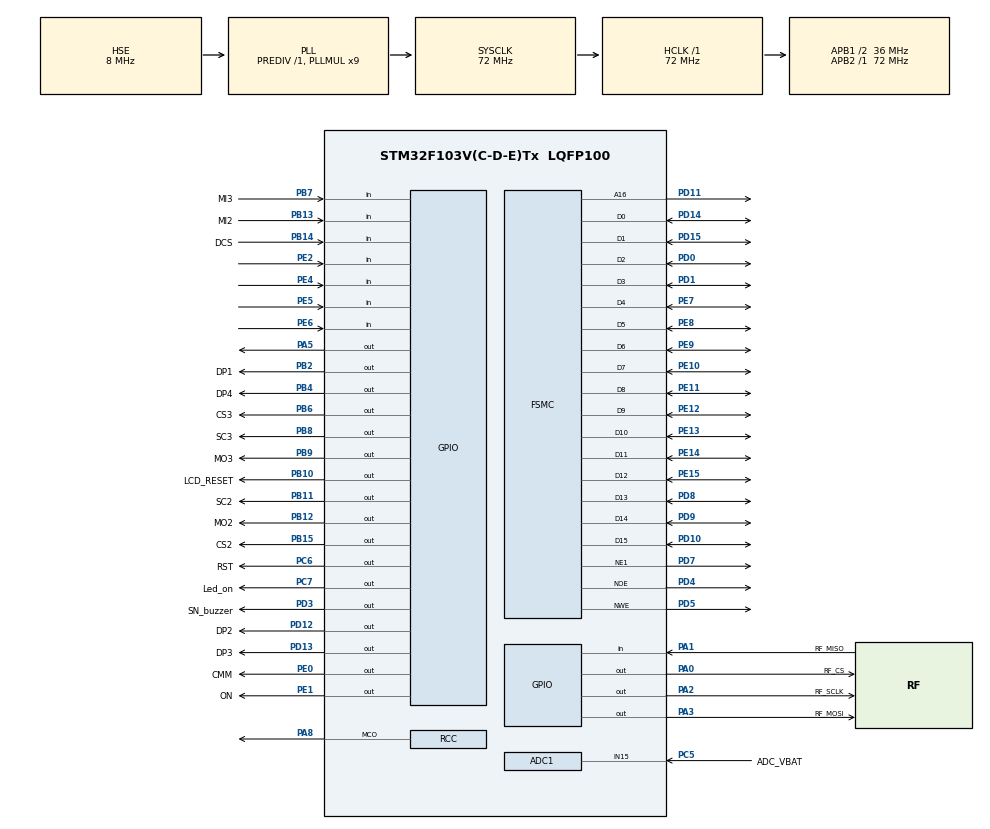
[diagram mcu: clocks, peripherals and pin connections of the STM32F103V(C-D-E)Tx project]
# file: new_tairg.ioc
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ADC1.Channel-1\#ChannelRegularConversion=ADC_CHANNEL_15
ADC1.ExternalTrigConv=ADC_EXTERNALTRIGCONV_T8_TRGO
ADC1.NbrOfConversion=1
ADC1.NbrOfConversionFlag=1
ADC1.Rank-1\#ChannelRegularConversion=1
ADC1.SamplingTime-1\#ChannelRegularConversion=ADC_SAMPLETIME_239CYCLES_5
ADC1.master=1
Dma.ADC1.0.Direction=DMA_PERIPH_TO_MEMORY
Dma.ADC1.0.Instance=DMA1_Channel1
Dma.ADC1.0.MemDataAlignment=DMA_MDATAALIGN_HALFWORD
Dma.ADC1.0.MemInc=DMA_MINC_ENABLE
Dma.ADC1.0.Mode=DMA_CIRCULAR
Dma.ADC1.0.PeriphDataAlignment=DMA_PDATAALIGN_HALFWORD
Dma.ADC1.0.PeriphInc=DMA_PINC_DISABLE
Dma.ADC1.0.Priority=DMA_PRIORITY_LOW
Dma.Request0=ADC1
FREERTOS.Tasks01=defaultTask,0,1024,StartDefaultTask,Default,NULL,Dynamic,NULL,NULL;kbTask,0,1024,kbTaskProc,Default,NULL,Dynamic,NULL,NULL;MeasureTask,0,512,MeasureTaskProc,Default,NULL,Dynamic,NULL,NULL;rfTask,0,256,RfTaskStart,Default,NULL,Dynamic,NULL,NULL
FREERTOS.configCHECK_FOR_STACK_OVERFLOW=2
FREERTOS.configRECORD_STACK_HIGH_ADDRESS=1
FREERTOS.configTOTAL_HEAP_SIZE=49000
FSMC.AddressSetupTime1=1
FSMC.BusTurnAroundDuration1=1
FSMC.DataSetupTime1=1
IWDG.Prescaler=IWDG_PRESCALER_256
IWDG.Reload=480
Mcu.Family=STM32F1
Mcu.Name=STM32F103V(C-D-E)Tx
Mcu.Package=LQFP100
NVIC.DMA1_Channel1_IRQn=true\:5\:0\:false\:false\:true\:true\:false\:true\:true
NVIC.PriorityGroup=NVIC_PRIORITYGROUP_4
NVIC.TIM7_IRQn=true\:0\:0\:false\:false\:true\:false\:false\:true\:true
NVIC.TimeBase=TIM7_IRQn
NVIC.TimeBaseIP=TIM7
OSC_IN.Mode=HSE-External-Oscillator
OSC_IN.Signal=RCC_OSC_IN
OSC_OUT.Mode=HSE-External-Oscillator
OSC_OUT.Signal=RCC_OSC_OUT
PA0-WKUP.GPIO_Label=RF_CS
PA0-WKUP.GPIO_Speed=GPIO_SPEED_FREQ_HIGH
PA0-WKUP.Signal=GPIO_Output
PA1.GPIO_Label=RF_MISO
PA1.Signal=GPIO_Input
PA13.Mode=JTAG_4_pins
PA13.Signal=SYS_JTMS-SWDIO
PA14.Mode=JTAG_4_pins
PA14.Signal=SYS_JTCK-SWCLK
PA15.Mode=JTAG_4_pins
PA15.Signal=SYS_JTDI
PA2.GPIO_Label=RF_SCLK
PA2.GPIO_Speed=GPIO_SPEED_FREQ_HIGH
PA2.Signal=GPIO_Output
PA3.GPIO_Label=RF_MOSI
PA3.GPIO_Speed=GPIO_SPEED_FREQ_HIGH
PA3.Signal=GPIO_Output
PA5.Signal=GPIO_Output
PA8.Mode=Clock-out
PA8.Signal=RCC_MCO
PB10.GPIO_Label=LCD_RESET
PB10.Signal=GPIO_Output
PB11.GPIO_Label=SC2
PB11.Signal=GPIO_Output
PB12.GPIO_Label=MO2
PB12.Signal=GPIO_Output
PB13.GPIO_Label=MI2
PB13.Signal=GPIO_Input
PB14.GPIO_Label=DCS
PB14.Signal=GPIO_Input
PB15.GPIO_Label=CS2
PB15.Signal=GPIO_Output
PB2.GPIO_Label=DP1
PB2.Signal=GPIO_Output
PB3.Mode=JTAG_4_pins
PB3.Signal=SYS_JTDO-TRACESWO
PB4.GPIO_Label=DP4
PB4.Signal=GPIO_Output
PB6.GPIO_Label=CS3
PB6.GPIO_Speed=GPIO_SPEED_FREQ_HIGH
PB6.PinState=GPIO_PIN_SET
PB6.Signal=GPIO_Output
PB7.GPIO_Label=MI3
PB7.Signal=GPIO_Input
PB8.GPIO_Label=SC3
PB8.GPIO_Speed=GPIO_SPEED_FREQ_HIGH
PB8.Signal=GPIO_Output
PB9.GPIO_Label=MO3
PB9.Signal=GPIO_Output
PC14-OSC32_IN.Mode=LSE-External-Oscillator
PC14-OSC32_IN.Signal=RCC_OSC32_IN
PC15-OSC32_OUT.Mode=LSE-External-Oscillator
PC15-OSC32_OUT.Signal=RCC_OSC32_OUT
PC5.GPIO_Label=ADC_VBAT
PC5.Signal=ADCx_IN15
PC6.GPIO_Label=RST
PC6.Signal=GPIO_Output
PC7.GPIO_Label=Led_on
PC7.PinState=GPIO_PIN_RESET
PC7.Signal=GPIO_Output
PD0.Mode=16b-d1
PD0.Signal=FSMC_D2
PD1.Mode=16b-d1
PD1.Signal=FSMC_D3
PD10.Mode=16b-d1
PD10.Signal=FSMC_D15
PD11.Mode=A16_1
PD11.Signal=FSMC_A16
PD12.GPIO_Label=DP2
PD12.Signal=GPIO_Output
PD13.GPIO_Label=DP3
PD13.Signal=GPIO_Output
PD14.Mode=16b-d1
PD14.Signal=FSMC_D0
PD15.Mode=16b-d1
PD15.Signal=FSMC_D1
PD3.GPIO_Label=SN_buzzer
PD3.Signal=GPIO_Output
PD4.Mode=Lcd1
PD4.Signal=FSMC_NOE
PD5.Mode=Lcd1
PD5.Signal=FSMC_NWE
PD7.Mode=NorPsramChipSelect1_1
PD7.Signal=FSMC_NE1
PD8.Mode=16b-d1
PD8.Signal=FSMC_D13
PD9.Mode=16b-d1
PD9.Signal=FSMC_D14
PE0.GPIO_Label=CMM
PE0.Signal=GPIO_Output
PE1.GPIO_Label=ON
PE1.PinState=GPIO_PIN_SET
PE1.Signal=GPIO_Output
PE10.Mode=16b-d1
PE10.Signal=FSMC_D7
PE11.Mode=16b-d1
PE11.Signal=FSMC_D8
PE12.Mode=16b-d1
PE12.Signal=FSMC_D9
PE13.Mode=16b-d1
PE13.Signal=FSMC_D10
PE14.Mode=16b-d1
PE14.Signal=FSMC_D11
PE15.Mode=16b-d1
PE15.Signal=FSMC_D12
PE2.Signal=GPIO_Input
PE4.GPIO_PuPd=GPIO_PULLUP
PE4.Signal=GPIO_Input
PE5.GPIO_PuPd=GPIO_PULLUP
PE5.Signal=GPIO_Input
PE6.GPIO_PuPd=GPIO_PULLUP
PE6.Signal=GPIO_Input
PE7.Mode=16b-d1
PE7.Signal=FSMC_D4
PE8.Mode=16b-d1
PE8.Signal=FSMC_D5
PE9.Mode=16b-d1
PE9.Signal=FSMC_D6
ProjectManager.HeapSize=0x0
ProjectManager.StackSize=0x400
ProjectManager.TargetToolchain=STM32CubeIDE
RCC.ADCPresc=RCC_ADCPCLK2_DIV6
RCC.AHBFreq_Value=72000000
RCC.APB1CLKDivider=RCC_HCLK_DIV2
RCC.APB1Freq_Value=36000000
RCC.APB1TimFreq_Value=72000000
RCC.APB2Freq_Value=72000000
RCC.APB2TimFreq_Value=72000000
RCC.HCLKFreq_Value=72000000
RCC.PLLMUL=RCC_PLL_MUL9
RCC.PLLSourceVirtual=RCC_PLLSOURCE_HSE
RCC.RCC_MCOSource=RCC_MCO1SOURCE_HSE
RCC.RTCClockSelection=RCC_RTCCLKSOURCE_LSE
RCC.SYSCLKFreq_VALUE=72000000
RCC.SYSCLKSource=RCC_SYSCLKSOURCE_PLLCLK
RCC.USBFreq_Value=48000000
RCC.USBPrescaler=RCC_USBCLKSOURCE_PLL_DIV1_5
SH.ADCx_IN15.0=ADC1_IN15,IN15
TIM8.Period=1000
TIM8.Prescaler=71
TIM8.TIM_MasterOutputTrigger=TIM_TRGO_UPDATE
TIM8.TIM_MasterSlaveMode=TIM_MASTERSLAVEMODE_ENABLE
VP_FREERTOS_VS_CMSIS_V1.Mode=CMSIS_V1
VP_IWDG_VS_IWDG.Mode=IWDG_Activate
VP_RTC_VS_RTC_Activate.Mode=RTC_Enabled
VP_SYS_VS_tim7.Mode=TIM7
VP_TIM8_VS_ClockSourceINT.Mode=Internal
board=custom

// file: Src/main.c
/* USER CODE BEGIN Header */
/**
  ******************************************************************************
  * @file           : main.c
  * @brief          : Main program body
  ******************************************************************************
  * This notice applies to any and all portions of this file
  * that are not between comment pairs USER CODE BEGIN and
  * USER CODE END. Other portions of this file, whether
  * inserted by the user or by software development tools
  * are owned by their respective copyright owners.
  *
  * Copyright (c) 2019 STMicroelectronics International N.V.
  * All rights reserved.
  *
  * Redistribution and use in source and binary forms, with or without
  * modification, are permitted, provided that the following conditions are met:
  *
  * 1. Redistribution of source code must retain the above copyright notice,
  *    this list of conditions and the following disclaimer.
  * 2. Redistributions in binary form must reproduce the above copyright notice,
  *    this list of conditions and the following disclaimer in the documentation
  *    and/or other materials provided with the distribution.
  * 3. Neither the name of STMicroelectronics nor the names of other
  *    contributors to this software may be used to endorse or promote products
  *    derived from this software without specific written permission.
  * 4. This software, including modifications and/or derivative works of this
  *    software, must execute solely and exclusively on microcontroller or
  *    microprocessor devices manufactured by or for STMicroelectronics.
  * 5. Redistribution and use of this software other than as permitted under
  *    this license is void and will automatically terminate your rights under
  *    this license.
  *
  * THIS SOFTWARE IS PROVIDED BY STMICROELECTRONICS AND CONTRIBUTORS "AS IS"
  * AND ANY EXPRESS, IMPLIED OR STATUTORY WARRANTIES, INCLUDING, BUT NOT
  * LIMITED TO, THE IMPLIED WARRANTIES OF MERCHANTABILITY, FITNESS FOR A
  * PARTICULAR PURPOSE AND NON-INFRINGEMENT OF THIRD PARTY INTELLECTUAL PROPERTY
  * RIGHTS ARE DISCLAIMED TO THE FULLEST EXTENT PERMITTED BY LAW. IN NO EVENT
  * SHALL STMICROELECTRONICS OR CONTRIBUTORS BE LIABLE FOR ANY DIRECT, INDIRECT,
  * INCIDENTAL, SPECIAL, EXEMPLARY, OR CONSEQUENTIAL DAMAGES (INCLUDING, BUT NOT
  * LIMITED TO, PROCUREMENT OF SUBSTITUTE GOODS OR SERVICES; LOSS OF USE, DATA,
  * OR PROFITS; OR BUSINESS INTERRUPTION) HOWEVER CAUSED AND ON ANY THEORY OF
  * LIABILITY, WHETHER IN CONTRACT, STRICT LIABILITY, OR TORT (INCLUDING
  * NEGLIGENCE OR OTHERWISE) ARISING IN ANY WAY OUT OF THE USE OF THIS SOFTWARE,
  * EVEN IF ADVISED OF THE POSSIBILITY OF SUCH DAMAGE.
  *
  ******************************************************************************
  */
/* USER CODE END Header */
#include "main.h"
#include "cmsis_os.h"

 ADC_HandleTypeDef hadc1;
DMA_HandleTypeDef hdma_adc1;

IWDG_HandleTypeDef hiwdg;

RTC_HandleTypeDef hrtc;

TIM_HandleTypeDef htim8;

SRAM_HandleTypeDef hsram1;

osThreadId defaultTaskHandle;
osThreadId kbTaskHandle;
osThreadId MeasureTaskHandle;
osThreadId rfTaskHandle;
/* USER CODE BEGIN PV */
/* Private variables ---------------------------------------------------------*/

/* USER CODE END PV */

void SystemClock_Config(void);
static void MX_GPIO_Init(void);
static void MX_DMA_Init(void);
static void MX_FSMC_Init(void);
static void MX_ADC1_Init(void);
static void MX_RTC_Init(void);
static void MX_TIM8_Init(void);
static void MX_IWDG_Init(void);
void StartDefaultTask(void const * argument);
void kbTaskProc(void const * argument);
void MeasureTaskProc(void const * argument);
void RfTaskStart(void const * argument);

/* USER CODE BEGIN PFP */
/* Private function prototypes -----------------------------------------------*/

/* USER CODE END PFP */

int main(void)
{

  /* MCU Configuration--------------------------------------------------------*/

  /* Reset of all peripherals, Initializes the Flash interface and the Systick. */
  HAL_Init();

  /* Configure the system clock */
  SystemClock_Config();

  /* Initialize all configured peripherals */
  MX_GPIO_Init();
  MX_DMA_Init();
  MX_FSMC_Init();
  MX_ADC1_Init();
  MX_RTC_Init();
  MX_TIM8_Init();
  MX_IWDG_Init();
  /* USER CODE BEGIN 2 */
  init();
  /* USER CODE END 2 */

  /* Create the thread(s) */
  /* definition and creation of defaultTask */
  osThreadDef(defaultTask, StartDefaultTask, osPriorityNormal, 0, 1024);
  defaultTaskHandle = osThreadCreate(osThread(defaultTask), NULL);

  /* definition and creation of kbTask */
  osThreadDef(kbTask, kbTaskProc, osPriorityNormal, 0, 1024);
  kbTaskHandle = osThreadCreate(osThread(kbTask), NULL);

  /* definition and creation of MeasureTask */
  osThreadDef(MeasureTask, MeasureTaskProc, osPriorityNormal, 0, 512);
  MeasureTaskHandle = osThreadCreate(osThread(MeasureTask), NULL);

  /* definition and creation of rfTask */
  osThreadDef(rfTask, RfTaskStart, osPriorityNormal, 0, 256);
  rfTaskHandle = osThreadCreate(osThread(rfTask), NULL);

  /* Start scheduler */
  osKernelStart();

  /* We should never get here as control is now taken by the scheduler */
  /* Infinite loop */
  while (1)
  {

  }
}

void SystemClock_Config(void)
{
  RCC_OscInitTypeDef RCC_OscInitStruct = {0};
  RCC_ClkInitTypeDef RCC_ClkInitStruct = {0};
  RCC_PeriphCLKInitTypeDef PeriphClkInit = {0};

  /** Initializes the RCC Oscillators according to the specified parameters
  * in the RCC_OscInitTypeDef structure.
  */
  RCC_OscInitStruct.OscillatorType = RCC_OSCILLATORTYPE_LSI|RCC_OSCILLATORTYPE_HSE
                              |RCC_OSCILLATORTYPE_LSE;
  RCC_OscInitStruct.HSEState = RCC_HSE_ON;
  RCC_OscInitStruct.HSEPredivValue = RCC_HSE_PREDIV_DIV1;
  RCC_OscInitStruct.LSEState = RCC_LSE_ON;
  RCC_OscInitStruct.HSIState = RCC_HSI_ON;
  RCC_OscInitStruct.LSIState = RCC_LSI_ON;
  RCC_OscInitStruct.PLL.PLLState = RCC_PLL_ON;
  RCC_OscInitStruct.PLL.PLLSource = RCC_PLLSOURCE_HSE;
  RCC_OscInitStruct.PLL.PLLMUL = RCC_PLL_MUL9;
  if (HAL_RCC_OscConfig(&RCC_OscInitStruct) != HAL_OK)
  {
    Error_Handler();
  }

  /** Initializes the CPU, AHB and APB buses clocks
  */
  RCC_ClkInitStruct.ClockType = RCC_CLOCKTYPE_HCLK|RCC_CLOCKTYPE_SYSCLK
                              |RCC_CLOCKTYPE_PCLK1|RCC_CLOCKTYPE_PCLK2;
  RCC_ClkInitStruct.SYSCLKSource = RCC_SYSCLKSOURCE_PLLCLK;
  RCC_ClkInitStruct.AHBCLKDivider = RCC_SYSCLK_DIV1;
  RCC_ClkInitStruct.APB1CLKDivider = RCC_HCLK_DIV2;
  RCC_ClkInitStruct.APB2CLKDivider = RCC_HCLK_DIV1;

  if (HAL_RCC_ClockConfig(&RCC_ClkInitStruct, FLASH_LATENCY_2) != HAL_OK)
  {
    Error_Handler();
  }
  PeriphClkInit.PeriphClockSelection = RCC_PERIPHCLK_RTC|RCC_PERIPHCLK_ADC;
  PeriphClkInit.RTCClockSelection = RCC_RTCCLKSOURCE_LSE;
  PeriphClkInit.AdcClockSelection = RCC_ADCPCLK2_DIV6;
  if (HAL_RCCEx_PeriphCLKConfig(&PeriphClkInit) != HAL_OK)
  {
    Error_Handler();
  }
  HAL_RCC_MCOConfig(RCC_MCO, RCC_MCO1SOURCE_HSE, RCC_MCODIV_1);
}

static void MX_ADC1_Init(void)
{

  ADC_ChannelConfTypeDef sConfig = {0};

  /** Common config
  */
  hadc1.Instance = ADC1;
  hadc1.Init.ScanConvMode = ADC_SCAN_DISABLE;
  hadc1.Init.ContinuousConvMode = DISABLE;
  hadc1.Init.DiscontinuousConvMode = DISABLE;
  hadc1.Init.ExternalTrigConv = ADC_EXTERNALTRIGCONV_T8_TRGO;
  hadc1.Init.DataAlign = ADC_DATAALIGN_RIGHT;
  hadc1.Init.NbrOfConversion = 1;
  if (HAL_ADC_Init(&hadc1) != HAL_OK)
  {
    Error_Handler();
  }

  /** Enable or disable the remapping of ADC1_ETRGREG:
  * ADC1 External Event regular conversion is connected to TIM8 TRG0
  */
  __HAL_AFIO_REMAP_ADC1_ETRGREG_ENABLE();

  /** Configure Regular Channel
  */
  sConfig.Channel = ADC_CHANNEL_15;
  sConfig.Rank = ADC_REGULAR_RANK_1;
  sConfig.SamplingTime = ADC_SAMPLETIME_239CYCLES_5;
  if (HAL_ADC_ConfigChannel(&hadc1, &sConfig) != HAL_OK)
  {
    Error_Handler();
  }

}

static void MX_IWDG_Init(void)
{

  hiwdg.Instance = IWDG;
  hiwdg.Init.Prescaler = IWDG_PRESCALER_256;
  hiwdg.Init.Reload = 480;
  if (HAL_IWDG_Init(&hiwdg) != HAL_OK)
  {
    Error_Handler();
  }

}

static void MX_RTC_Init(void)
{

  /** Initialize RTC Only
  */
  hrtc.Instance = RTC;
  hrtc.Init.AsynchPrediv = RTC_AUTO_1_SECOND;
  hrtc.Init.OutPut = RTC_OUTPUTSOURCE_ALARM;
  if (HAL_RTC_Init(&hrtc) != HAL_OK)
  {
    Error_Handler();
  }

}

static void MX_TIM8_Init(void)
{

  TIM_ClockConfigTypeDef sClockSourceConfig = {0};
  TIM_MasterConfigTypeDef sMasterConfig = {0};

  htim8.Instance = TIM8;
  htim8.Init.Prescaler = 71;
  htim8.Init.CounterMode = TIM_COUNTERMODE_UP;
  htim8.Init.Period = 1000;
  htim8.Init.ClockDivision = TIM_CLOCKDIVISION_DIV1;
  htim8.Init.RepetitionCounter = 0;
  htim8.Init.AutoReloadPreload = TIM_AUTORELOAD_PRELOAD_DISABLE;
  if (HAL_TIM_Base_Init(&htim8) != HAL_OK)
  {
    Error_Handler();
  }
  sClockSourceConfig.ClockSource = TIM_CLOCKSOURCE_INTERNAL;
  if (HAL_TIM_ConfigClockSource(&htim8, &sClockSourceConfig) != HAL_OK)
  {
    Error_Handler();
  }
  sMasterConfig.MasterOutputTrigger = TIM_TRGO_UPDATE;
  sMasterConfig.MasterSlaveMode = TIM_MASTERSLAVEMODE_ENABLE;
  if (HAL_TIMEx_MasterConfigSynchronization(&htim8, &sMasterConfig) != HAL_OK)
  {
    Error_Handler();
  }

}

static void MX_DMA_Init(void)
{

  /* DMA controller clock enable */
  __HAL_RCC_DMA1_CLK_ENABLE();

  /* DMA interrupt init */
  /* DMA1_Channel1_IRQn interrupt configuration */
  HAL_NVIC_SetPriority(DMA1_Channel1_IRQn, 5, 0);
  HAL_NVIC_EnableIRQ(DMA1_Channel1_IRQn);

}

static void MX_GPIO_Init(void)
{
  GPIO_InitTypeDef GPIO_InitStruct = {0};

  /* GPIO Ports Clock Enable */
  __HAL_RCC_GPIOE_CLK_ENABLE();
  __HAL_RCC_GPIOC_CLK_ENABLE();
  __HAL_RCC_GPIOA_CLK_ENABLE();
  __HAL_RCC_GPIOB_CLK_ENABLE();
  __HAL_RCC_GPIOD_CLK_ENABLE();

  /*Configure GPIO pin Output Level */
  HAL_GPIO_WritePin(GPIOA, RF_CS_Pin|RF_SCLK_Pin|RF_MOSI_Pin|GPIO_PIN_5, GPIO_PIN_RESET);

  /*Configure GPIO pin Output Level */
  HAL_GPIO_WritePin(GPIOB, DP1_Pin|LCD_RESET_Pin|SC2_Pin|MO2_Pin
                          |CS2_Pin|DP4_Pin|SC3_Pin|MO3_Pin, GPIO_PIN_RESET);

  /*Configure GPIO pin Output Level */
  HAL_GPIO_WritePin(GPIOD, DP2_Pin|DP3_Pin|SN_buzzer_Pin, GPIO_PIN_RESET);

  /*Configure GPIO pin Output Level */
  HAL_GPIO_WritePin(GPIOC, RST_Pin|Led_on_Pin, GPIO_PIN_RESET);

  /*Configure GPIO pin Output Level */
  HAL_GPIO_WritePin(CS3_GPIO_Port, CS3_Pin, GPIO_PIN_SET);

  /*Configure GPIO pin Output Level */
  HAL_GPIO_WritePin(CMM_GPIO_Port, CMM_Pin, GPIO_PIN_RESET);

  /*Configure GPIO pin Output Level */
  HAL_GPIO_WritePin(ON_GPIO_Port, ON_Pin, GPIO_PIN_SET);

  /*Configure GPIO pin : PE2 */
  GPIO_InitStruct.Pin = GPIO_PIN_2;
  GPIO_InitStruct.Mode = GPIO_MODE_INPUT;
  GPIO_InitStruct.Pull = GPIO_NOPULL;
  HAL_GPIO_Init(GPIOE, &GPIO_InitStruct);

  /*Configure GPIO pin : PE3 */
  GPIO_InitStruct.Pin = GPIO_PIN_3;
  GPIO_InitStruct.Mode = GPIO_MODE_ANALOG;
  HAL_GPIO_Init(GPIOE, &GPIO_InitStruct);

  /*Configure GPIO pins : PE4 PE5 PE6 */
  GPIO_InitStruct.Pin = GPIO_PIN_4|GPIO_PIN_5|GPIO_PIN_6;
  GPIO_InitStruct.Mode = GPIO_MODE_INPUT;
  GPIO_InitStruct.Pull = GPIO_PULLUP;
  HAL_GPIO_Init(GPIOE, &GPIO_InitStruct);

  /*Configure GPIO pins : PC13 PC0 PC1 PC2
                           PC3 PC4 PC8 PC9
                           PC10 PC11 PC12 */
  GPIO_InitStruct.Pin = GPIO_PIN_13|GPIO_PIN_0|GPIO_PIN_1|GPIO_PIN_2
                          |GPIO_PIN_3|GPIO_PIN_4|GPIO_PIN_8|GPIO_PIN_9
                          |GPIO_PIN_10|GPIO_PIN_11|GPIO_PIN_12;
  GPIO_InitStruct.Mode = GPIO_MODE_ANALOG;
  HAL_GPIO_Init(GPIOC, &GPIO_InitStruct);

  /*Configure GPIO pins : RF_CS_Pin RF_SCLK_Pin RF_MOSI_Pin */
  GPIO_InitStruct.Pin = RF_CS_Pin|RF_SCLK_Pin|RF_MOSI_Pin;
  GPIO_InitStruct.Mode = GPIO_MODE_OUTPUT_PP;
  GPIO_InitStruct.Pull = GPIO_NOPULL;
  GPIO_InitStruct.Speed = GPIO_SPEED_FREQ_HIGH;
  HAL_GPIO_Init(GPIOA, &GPIO_InitStruct);

  /*Configure GPIO pin : RF_MISO_Pin */
  GPIO_InitStruct.Pin = RF_MISO_Pin;
  GPIO_InitStruct.Mode = GPIO_MODE_INPUT;
  GPIO_InitStruct.Pull = GPIO_NOPULL;
  HAL_GPIO_Init(RF_MISO_GPIO_Port, &GPIO_InitStruct);

  /*Configure GPIO pins : PA4 PA6 PA7 PA9
                           PA10 PA11 PA12 */
  GPIO_InitStruct.Pin = GPIO_PIN_4|GPIO_PIN_6|GPIO_PIN_7|GPIO_PIN_9
                          |GPIO_PIN_10|GPIO_PIN_11|GPIO_PIN_12;
  GPIO_InitStruct.Mode = GPIO_MODE_ANALOG;
  HAL_GPIO_Init(GPIOA, &GPIO_InitStruct);

  /*Configure GPIO pin : PA5 */
  GPIO_InitStruct.Pin = GPIO_PIN_5;
  GPIO_InitStruct.Mode = GPIO_MODE_OUTPUT_PP;
  GPIO_InitStruct.Pull = GPIO_NOPULL;
  GPIO_InitStruct.Speed = GPIO_SPEED_FREQ_LOW;
  HAL_GPIO_Init(GPIOA, &GPIO_InitStruct);

  /*Configure GPIO pins : PB0 PB1 PB5 */
  GPIO_InitStruct.Pin = GPIO_PIN_0|GPIO_PIN_1|GPIO_PIN_5;
  GPIO_InitStruct.Mode = GPIO_MODE_ANALOG;
  HAL_GPIO_Init(GPIOB, &GPIO_InitStruct);

  /*Configure GPIO pins : DP1_Pin LCD_RESET_Pin SC2_Pin MO2_Pin
                           CS2_Pin DP4_Pin MO3_Pin */
  GPIO_InitStruct.Pin = DP1_Pin|LCD_RESET_Pin|SC2_Pin|MO2_Pin
                          |CS2_Pin|DP4_Pin|MO3_Pin;
  GPIO_InitStruct.Mode = GPIO_MODE_OUTPUT_PP;
  GPIO_InitStruct.Pull = GPIO_NOPULL;
  GPIO_InitStruct.Speed = GPIO_SPEED_FREQ_LOW;
  HAL_GPIO_Init(GPIOB, &GPIO_InitStruct);

  /*Configure GPIO pins : MI2_Pin DCS_Pin MI3_Pin */
  GPIO_InitStruct.Pin = MI2_Pin|DCS_Pin|MI3_Pin;
  GPIO_InitStruct.Mode = GPIO_MODE_INPUT;
  GPIO_InitStruct.Pull = GPIO_NOPULL;
  HAL_GPIO_Init(GPIOB, &GPIO_InitStruct);

  /*Configure GPIO pins : DP2_Pin DP3_Pin SN_buzzer_Pin */
  GPIO_InitStruct.Pin = DP2_Pin|DP3_Pin|SN_buzzer_Pin;
  GPIO_InitStruct.Mode = GPIO_MODE_OUTPUT_PP;
  GPIO_InitStruct.Pull = GPIO_NOPULL;
  GPIO_InitStruct.Speed = GPIO_SPEED_FREQ_LOW;
  HAL_GPIO_Init(GPIOD, &GPIO_InitStruct);

  /*Configure GPIO pins : RST_Pin Led_on_Pin */
  GPIO_InitStruct.Pin = RST_Pin|Led_on_Pin;
  GPIO_InitStruct.Mode = GPIO_MODE_OUTPUT_PP;
  GPIO_InitStruct.Pull = GPIO_NOPULL;
  GPIO_InitStruct.Speed = GPIO_SPEED_FREQ_LOW;
  HAL_GPIO_Init(GPIOC, &GPIO_InitStruct);

  /*Configure GPIO pin : PA8 */
  GPIO_InitStruct.Pin = GPIO_PIN_8;
  GPIO_InitStruct.Mode = GPIO_MODE_AF_PP;
  GPIO_InitStruct.Speed = GPIO_SPEED_FREQ_LOW;
  HAL_GPIO_Init(GPIOA, &GPIO_InitStruct);

  /*Configure GPIO pins : PD2 PD6 */
  GPIO_InitStruct.Pin = GPIO_PIN_2|GPIO_PIN_6;
  GPIO_InitStruct.Mode = GPIO_MODE_ANALOG;
  HAL_GPIO_Init(GPIOD, &GPIO_InitStruct);

  /*Configure GPIO pins : CS3_Pin SC3_Pin */
  GPIO_InitStruct.Pin = CS3_Pin|SC3_Pin;
  GPIO_InitStruct.Mode = GPIO_MODE_OUTPUT_PP;
  GPIO_InitStruct.Pull = GPIO_NOPULL;
  GPIO_InitStruct.Speed = GPIO_SPEED_FREQ_HIGH;
  HAL_GPIO_Init(GPIOB, &GPIO_InitStruct);

  /*Configure GPIO pins : CMM_Pin ON_Pin */
  GPIO_InitStruct.Pin = CMM_Pin|ON_Pin;
  GPIO_InitStruct.Mode = GPIO_MODE_OUTPUT_PP;
  GPIO_InitStruct.Pull = GPIO_NOPULL;
  GPIO_InitStruct.Speed = GPIO_SPEED_FREQ_LOW;
  HAL_GPIO_Init(GPIOE, &GPIO_InitStruct);

}

/* FSMC initialization function */
static void MX_FSMC_Init(void)
{

  FSMC_NORSRAM_TimingTypeDef Timing = {0};

  /** Perform the SRAM1 memory initialization sequence
  */
  hsram1.Instance = FSMC_NORSRAM_DEVICE;
  hsram1.Extended = FSMC_NORSRAM_EXTENDED_DEVICE;
  /* hsram1.Init */
  hsram1.Init.NSBank = FSMC_NORSRAM_BANK1;
  hsram1.Init.DataAddressMux = FSMC_DATA_ADDRESS_MUX_DISABLE;
  hsram1.Init.MemoryType = FSMC_MEMORY_TYPE_SRAM;
  hsram1.Init.MemoryDataWidth = FSMC_NORSRAM_MEM_BUS_WIDTH_16;
  hsram1.Init.BurstAccessMode = FSMC_BURST_ACCESS_MODE_DISABLE;
  hsram1.Init.WaitSignalPolarity = FSMC_WAIT_SIGNAL_POLARITY_LOW;
  hsram1.Init.WrapMode = FSMC_WRAP_MODE_DISABLE;
  hsram1.Init.WaitSignalActive = FSMC_WAIT_TIMING_BEFORE_WS;
  hsram1.Init.WriteOperation = FSMC_WRITE_OPERATION_ENABLE;
  hsram1.Init.WaitSignal = FSMC_WAIT_SIGNAL_DISABLE;
  hsram1.Init.ExtendedMode = FSMC_EXTENDED_MODE_DISABLE;
  hsram1.Init.AsynchronousWait = FSMC_ASYNCHRONOUS_WAIT_DISABLE;
  hsram1.Init.WriteBurst = FSMC_WRITE_BURST_DISABLE;
  /* Timing */
  Timing.AddressSetupTime = 1;
  Timing.AddressHoldTime = 15;
  Timing.DataSetupTime = 1;
  Timing.BusTurnAroundDuration = 1;
  Timing.CLKDivision = 16;
  Timing.DataLatency = 17;
  Timing.AccessMode = FSMC_ACCESS_MODE_A;
  /* ExtTiming */

  if (HAL_SRAM_Init(&hsram1, &Timing, NULL) != HAL_OK)
  {
    Error_Handler( );
  }

  /** Disconnect NADV
  */

  __HAL_AFIO_FSMCNADV_DISCONNECTED();

}

/* USER CODE BEGIN 4 */

int _getentropy (void *buffer, size_t length)
{
  return -1;
}

/* USER CODE END 4 */

void StartDefaultTask(void const * argument)
{
  /* USER CODE BEGIN 5 */
  main_task();
  /* USER CODE END 5 */
}

void kbTaskProc(void const * argument)
{
  /* USER CODE BEGIN kbTaskProc */
  /* Infinite loop */
  for(;;)
  {
    osDelay(10);
		kbtask();
  }
  /* USER CODE END kbTaskProc */
}

void MeasureTaskProc(void const * argument)
{
  /* USER CODE BEGIN MeasureTaskProc */
	measure_task();
  /* USER CODE END MeasureTaskProc */
}

void RfTaskStart(void const * argument)
{
  /* USER CODE BEGIN RfTaskStart */
  rf_task();
  /* USER CODE END RfTaskStart */
}

void HAL_TIM_PeriodElapsedCallback(TIM_HandleTypeDef *htim)
{
  if (htim->Instance == TIM7) {
    HAL_IncTick();
  }
}

void Error_Handler(void)
{
  while(1)
  {
  }
}

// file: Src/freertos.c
/* USER CODE BEGIN Header */
/**
  ******************************************************************************
  * File Name          : freertos.c
  * Description        : Code for freertos applications
  ******************************************************************************
  * @attention
  *
  * <h2><center>&copy; Copyright (c) 2019 STMicroelectronics.
  * All rights reserved.</center></h2>
  *
  * This software component is licensed by ST under Ultimate Liberty license
  * SLA0044, the "License"; You may not use this file except in compliance with
  * the License. You may obtain a copy of the License at:
  *                             www.st.com/SLA0044
  *
  ******************************************************************************
  */
/* USER CODE END Header */

#include "FreeRTOS.h"
#include "task.h"
#include "main.h"

/* GetIdleTaskMemory prototype (linked to static allocation support) */
void vApplicationGetIdleTaskMemory( StaticTask_t **ppxIdleTaskTCBBuffer, StackType_t **ppxIdleTaskStackBuffer, uint32_t *pulIdleTaskStackSize );

/* Hook prototypes */
void vApplicationStackOverflowHook(xTaskHandle xTask, signed char *pcTaskName);

/* USER CODE BEGIN 4 */
__weak void vApplicationStackOverflowHook(xTaskHandle xTask, signed char *pcTaskName)
{
   /* Run time stack overflow checking is performed if
   configCHECK_FOR_STACK_OVERFLOW is defined to 1 or 2. This hook function is
   called if a stack overflow is detected. */
}
/* USER CODE END 4 */

/* USER CODE BEGIN GET_IDLE_TASK_MEMORY */
static StaticTask_t xIdleTaskTCBBuffer;
static StackType_t xIdleStack[configMINIMAL_STACK_SIZE];

void vApplicationGetIdleTaskMemory( StaticTask_t **ppxIdleTaskTCBBuffer, StackType_t **ppxIdleTaskStackBuffer, uint32_t *pulIdleTaskStackSize )
{
  *ppxIdleTaskTCBBuffer = &xIdleTaskTCBBuffer;
  *ppxIdleTaskStackBuffer = &xIdleStack[0];
  *pulIdleTaskStackSize = configMINIMAL_STACK_SIZE;
  /* place for user code */
}
/* USER CODE END GET_IDLE_TASK_MEMORY */
